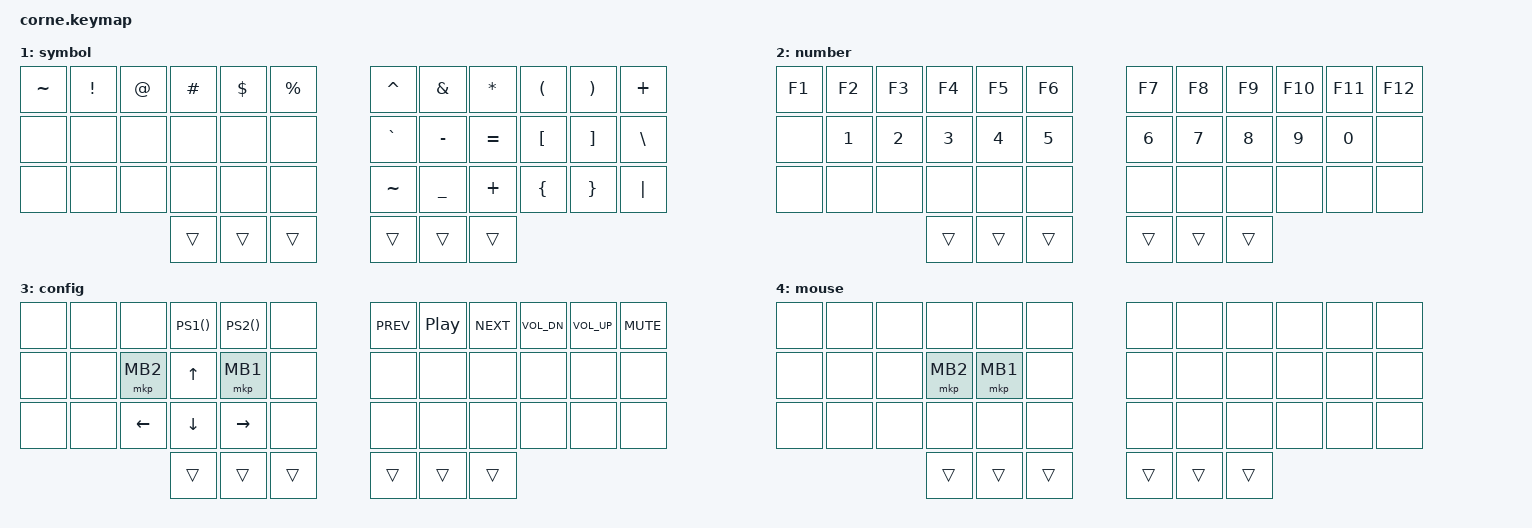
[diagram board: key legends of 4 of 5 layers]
/*
 * Copyright (c) 2020 The ZMK Contributors
 *
 * SPDX-License-Identifier: MIT
 */

#include <behaviors.dtsi>
#include <input/processors.dtsi>
#include <dt-bindings/zmk/keys.h>
#include <dt-bindings/zmk/bt.h>
#include <dt-bindings/zmk/pointing.h>

// homerow mod
// macOS: CAGS. Easier to chord Cmd+Shift, Cmd+Alt
#define HRL(k1,k2,k3,k4) &hml LCTRL k1 &hml LALT k2 &hml LGUI k3 &hml LSHFT k4
#define HRR(k1,k2,k3,k4) &hmr LSHFT k1 &hmr LGUI k2 &hmr LALT k3 &hmr LCTRL k4

// clear bt on hold
//#define BT_TGGL() &bt_toggle BT_CLR BT_NXT
#define BT_TGGL() &bt_toggle &bt_clr &bt_clr

// macOS print screen (Cmd+Shift+3, Cmd+Shift+4)
#define PS1() &kp LG(LS(N3))
#define PS2() &kp LG(LS(N4))

// key positions
#define LEFT_HOMEROW_POS() <13>, <14>, <15>, <16>
#define LEFT_THUMBROW_POS() <36>, <37>, <38>
#define RIGHT_HOMEROW_POS() <19>, <20>, <21>, <22>
#define RIGHT_THUMBROW_POS() <39>, <40>, <41>

#define LEFT_SIDE_POS()     <0>, <1>, <2>, <3>, <4>, <5>, \
                            <12>, <13>, <14>, <15>, <16>, <17>, \
                            <24>, <25>, <26>, <27>, <28>, <29>, \
                            <36>, <37>, <38>

#define RIGHT_SIDE_POS()    <6>, <7>, <8>, <9>, <10>, <11>, \
                            <18>, <19>, <20>, <21>, <22>, <23>, \
                            <30>, <31>, <32>, <33>, <34>, <35>, \
                            <39>, <40>, <41>

/ {
    /omit-if-no-ref/ zip_temp_layer: zip_temp_layer {
        compatible = "zmk,input-processor-temp-layer";
        #input-processor-cells = <2>;
        require-prior-idle-ms = <2000>;

        //key positions to exclude from deactivating the layer
        excluded-positions = <
          13 14 15 16   // left homerow
          19 20 21 22   // right homerow
          36 37 38      // left thumbrow
          39 49 41      // right thumbrow
        >;
    };

    conditional_layers {
        compatible = "zmk,conditional-layers";
        tri_layer {
            if-layers = <1 2>;
            then-layer = <3>;
        };
    };

    behaviors {
        hml: home_row_mod_left {
            compatible = "zmk,behavior-hold-tap";
            label = "homerow mod (left)";
            #binding-cells = <2>;
            flavor = "balanced";
            require-prior-idle-ms = <150>;
            tapping-term-ms = <280>;
            quick-tap-ms = <175>;
            bindings = <&kp>, <&kp>;
            // List of keys on the right side of the keyboard
            hold-trigger-key-positions = RIGHT_SIDE_POS();
            hold-trigger-on-release;
        };

        hmr: home_row_mod_right {
            compatible = "zmk,behavior-hold-tap";
            label = "homerow mod (right)";
            #binding-cells = <2>;
            flavor = "balanced";
            require-prior-idle-ms = <150>;
            tapping-term-ms = <280>;
            quick-tap-ms = <175>;
            bindings = <&kp>, <&kp>;
            // List of keys on the left side of the keyboard
            hold-trigger-key-positions = LEFT_SIDE_POS();
            hold-trigger-on-release;
        };
    };

    keymap {
        compatible = "zmk,keymap";

// Reasoning:
// preserves qwerty and special keys in familiar places (esc, tab, enter, backspace, space, gui, alt)
// homerow mods based on macOS frequency AND ease to chord frequent keys (Cmd+Shift, Cmd+Alt)
// Questions:
// Where to place `~ ? It's used for `, ~, Cmd+`(+Shift), Cmd+Opt+Esc
// How to chord: Cmd+(Opt+)Shift+3? Cmd+(Opt+)Shift+4?
// Should I have lower and raise on both sides?
        default_layer {
            display-name = "qwerty";
            bindings = <
// |----------|-------|------|---------|------|---------|    |----------|-------|----------|--------|---------|--------|
// | ESC      | Q     | W    | E       | R    | T       |    | Y        | U     | I        | O      | P       | BKSP   |
    &kp ESC    &kp Q   &kp W  &kp E     &kp R  &kp T          &kp Y      &kp U   &kp I      &kp O    &kp P     &kp BSPC
// |----------|-------|------|---------|------|---------|    |----------|-------|----------|--------|---------|--------|
// | TAB      | A/CTR | S/ALT| D/GUI   |F/SHFT| G       |    | H        | J/SHFT| K/GUI    | L/ALT  | ;/CTRL  |  '     |
    &kp TAB    HRL(A,  S,     D,        F)     &kp G          &kp H      HRR(J,  K,         L,       SEMI)     &kp SQT
// |----------|-------|------|---------|------|---------|    |----------|-------|----------|--------|---------|--------|
// | SHFT     | Z     | X    | C       | V    | B       |    | N        | M     | ,        |  .     |  /      | ENTER  |
    &kp LSHFT  &kp Z   &kp X  &kp C     &kp V  &kp B          &kp N      &kp M   &kp COMMA  &kp DOT  &kp FSLH  &kp RET
// |----------|-------|------|---------|------|---------|    |----------|-------|----------|--------|---------|--------|
//                           | GUI     | LWR  | SPC     |    | SPC      | RSE   | ALT      |
                              &kp LGUI  &mo 1  &kp SPACE      &kp SPACE  &mo 2   &kp RALT
//                           |---------|------|---------|    |----------|-------|----------|
            >;
        };


        lower_layer {
            display-name = "symbol";
            bindings = <
// |----------|---------|---------|---------|---------|---------|    |----------|----------|-----------|---------|---------|---------|
// | ~        | !       | @       | #       | $       | %       |    | ^        | &        | *         | (       | )       | +       |
    &kp TILDE  &kp EXCL  &kp AT    &kp HASH  &kp DLLR  &kp PRCNT      &kp CARET  &kp AMPS   &kp STAR    &kp LPAR  &kp RPAR  &kp PLUS
// |----------|---------|---------|---------|---------|---------|    |----------|----------|-----------|---------|---------|-------- |
// |          |         |         |         |         |         |    | `        | -        | =         | [       | ]       | \       |
    &none      &none     &none     &none     &none    &none          &kp GRAVE  &kp MINUS  &kp EQUAL  &kp LBKT  &kp RBKT  &kp BSLH
// |----------|---------|---------|---------|---------|---------|    |----------|----------|-----------|---------|---------|-------- |
// |          |         |         |         |         |         |    | ~        | _        | +         | {       | }       | "|"     |
    &none      &none     &none     &none     &none     &none          &kp TILDE  &kp UNDER  &kp PLUS    &kp LBRC  &kp RBRC  &kp PIPE
// |----------|---------|---------|---------|---------|---------|    |----------|----------|-----------|---------|---------|-------- |
//                                |         |         |         |    |          |          |           |
														       &trans    &trans    &trans         &trans     &trans     &trans
//                                |---------|---------|---------|    |----------|----------|-----------|
            >;
        };

        raise_layer {
            display-name = "number";
            bindings = <
// |-------|-------|-------|-------|-------|-------|    |-------|-------|-------|--------|--------|--------|
// | F1    | F2    | F3    | F4    | F5    | F6    |    | F7    | F8    | F9    | F10    | F11    | F12    |
    &kp F1  &kp F2  &kp F3  &kp F4  &kp F5  &kp F6       &kp F7  &kp F8  &kp F9  &kp F10  &kp F11  &kp F12
// |-------|-------|-------|-------|-------|-------|    |-------|-------|-------|--------|------- |--------|
// |       | 1     | 2     | 3     | 4     | 5     |    | 6     | 7     | 8     | 9      | 0      |        |
    &none   &kp N1  &kp N2  &kp N3  &kp N4  &kp N5       &kp N6  &kp N7  &kp N8  &kp N9   &kp N0   &none
// |-------|-------|-------|-------|-------|-------|    |-------|-------|-------|--------|--------|--------|
// |       |       |       |       |       |       |    |       |       |       |        |        |        |
    &none   &none   &none   &none   &none   &none        &none   &none   &none   &none    &none    &none
// |-------|-------|-------|-------|-------|-------|    |-------|-------|-------|--------|--------|--------|
//                         |       |       |       |    |       |       |       |
                            &trans  &trans  &trans       &trans  &trans  &trans
//                         |-------|-------|-------|    |-------|-------|-------|
            >;
        };


        middle_layer {
            display-name = "config";
            bindings = <
// |-------|-------|-------|-------|-------|-------|    |-------|-------|-------|--------|--------|--------|
// |       |       |       | PScr1 | PScr2 |       |    | <<    | Play  | >>    | Vol-   | Vol+   | Mute   |
    &none   &none   &none   PS1()   PS2()   &none        &kp C_PREV  &kp C_PP &kp C_NEXT &kp C_VOL_DN &kp C_VOL_UP &kp C_MUTE
// |-------|-------|-------|-------|-------|-------|    |-------|-------|-------|--------|--------|--------|
// |       |       |       | UP    |       |       |    |       |       |       |        |        |        |
    &none   &none   &mkp MB2   &kp UP  &mkp MB1   &none        &none   &none   &none   &none    &none    &none
// |-------|-------|-------|-------|-------|-------|    |-------|-------|-------|--------|--------|--------|
// |       |       | LEFT  | DOWN  | RIGHT |       |    |       |       |       |        |        |        |
    &none   &none   &kp LEFT &kp DOWN &kp RIGHT &none    &none   &none   &none   &none    &none    &none
// |-------|-------|-------|-------|-------|-------|    |-------|-------|-------|--------|--------|--------|
//                         |       |       |       |    |       |       |       |
                            &trans  &trans  &trans       &trans  &trans  &trans
//                         |-------|-------|-------|    |-------|-------|-------|
            >;
        };

        mouse_layer {
            display-name = "mouse";
            bindings = <
// |-------|-------|-------|-------|-------|-------|    |-------|-------|-------|--------|--------|--------|
// |       |       |       |       |       |       |    |       |       |       |        |        |        |
    &none   &none   &none   &none   &none   &none        &none   &none   &none   &none    &none    &none
// |-------|-------|-------|-------|-------|-------|    |-------|-------|-------|--------|--------|--------|
// |       |       |       |       |       |       |    |       |       |       |        |        |        |
    &none   &none   &none &mkp MB2  &mkp MB1 &none        &none   &none   &none   &none    &none    &none
// |-------|-------|-------|-------|-------|-------|    |-------|-------|-------|--------|--------|--------|
// |       |       |       |       |       |       |    |       |       |       |        |        |        |
    &none   &none   &none   &none   &none   &none        &none   &none   &none   &none    &none    &none
// |-------|-------|-------|-------|-------|-------|    |-------|-------|-------|--------|--------|--------|
//                         |       |       |       |    |       |       |       |
                            &trans  &trans  &trans       &trans  &trans  &trans
//                         |-------|-------|-------|    |-------|-------|-------|
            >;
        };

        extra_3 {
            status = "reserved";
        };
    };
};
